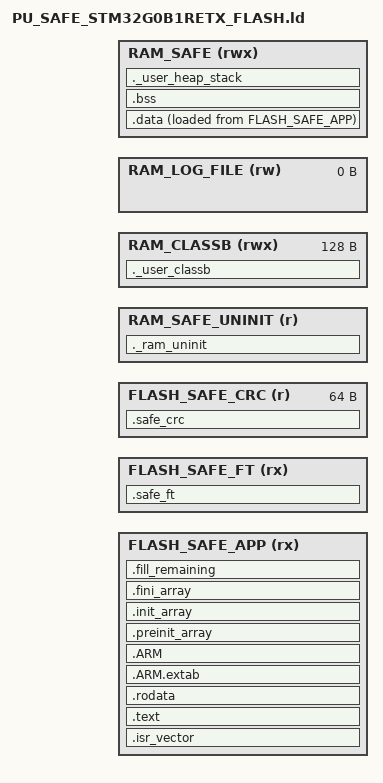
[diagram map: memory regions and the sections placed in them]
/**
 ******************************************************************************
 * @file      LinkerScript.ld
 * @author    Auto-generated by STM32CubeIDE
 * @brief     Linker script for STM32G0B1RETx Device from STM32G0 series
 *                      512Kbytes FLASH
 *                      144Kbytes RAM
 *
 *            Set heap size, stack size and stack location according
 *            to application requirements.
 *
 *            Set memory bank area and size if external memory is used
 ******************************************************************************
 * @attention
 *
 * <h2><center>&copy; Copyright (c) 2020 STMicroelectronics.
 * All rights reserved.</center></h2>
 *
 * This software component is licensed by ST under BSD 3-Clause license,
 * the "License"; You may not use this file except in compliance with the
 * License. You may obtain a copy of the License at:
 *                        opensource.org/licenses/BSD-3-Clause
 *
 ******************************************************************************
 */

/* External linker file common to SAFE and USER project where partitioning 
* of the FLASH and RAM between SAFE and USER project is set.
* All further partitioning of the FLASH and RAM in this file is within boundaries
* set in memory_definition.ld file.*/
INCLUDE ../../submodules/shared/memory_definition.ld


/* Entry Point */
ENTRY(Safe_Reset_Handler)



/*##########################################################################*/
/* Highest address of the user mode stack */
_estack = _MEMPART_RAM_SAFE_ADDR + _MEMPART_RAM_SAFE_SIZE;    /* end of "RAM" Ram type memory */

 

_Min_Heap_Size  = 0x400 ;    /* required amount of heap  */
_Min_Stack_Size = 0x800 ;    /* required amount of stack */

 

/* used at SAFE start to delete whole RAM (SAFE and USER) - NOT USED*/
_ram_start = _RAM_START_ADDR;
_ram_end   = _RAM_START_ADDR + _RAM_SIZE;
 

/* This is related to ClassB Flash CRC runtime check. */
/*Size of the SAFE app + SAFE Function table must be multiple of 64*/
/* CRC of SAFE flash image is located in the last 64 byte block */
/* of the Function table defined in the memory_definition.ld (see INCLUDE above) */
FLASH_SAFE_CRC_SIZE = 64; 

/* Put SAFE FLASH CRC at the end of SAFE_FNC_TABLE */
FLASH_SAFE_CRC_ADDR = _MEMPART_FLASH_SAFE_FNC_TABLE_ADDR + _MEMPART_FLASH_SAFE_FNC_TABLE_SIZE - FLASH_SAFE_CRC_SIZE;


/* Class B variables */
RAM_CLASSB_SIZE = 0x80;
RAM_CLASSB_ADDR = _MEMPART_RAM_SAFE_ADDR;

 /* USED for TEST logging */
RAM_LOG_FILE_SIZE = 0;
RAM_LOG_FILE_ADDR = RAM_CLASSB_ADDR + RAM_CLASSB_SIZE;
_MEMPART_RAM_LOG_FILE_ADDR = RAM_LOG_FILE_ADDR;

/* SAFE RAM minus CLASS B */
RAM_SAFE_MCB_ADDR = RAM_LOG_FILE_ADDR + RAM_LOG_FILE_SIZE; 
RAM_SAFE_MCB_SIZE = _MEMPART_RAM_SAFE_SIZE - RAM_CLASSB_SIZE - RAM_LOG_FILE_SIZE; 


/*##########################################################################*/
/* Memories definition */
MEMORY
{
    FLASH_SAFE_APP  (rx)    : ORIGIN = _MEMPART_FLASH_SAFE_APP_ADDR         ,LENGTH = _MEMPART_FLASH_SAFE_APP_SIZE 
    FLASH_SAFE_FT   (rx)    : ORIGIN = _MEMPART_FLASH_SAFE_FNC_TABLE_ADDR   ,LENGTH = _MEMPART_FLASH_SAFE_FNC_TABLE_SIZE - FLASH_SAFE_CRC_SIZE
    FLASH_SAFE_CRC  (r )    : ORIGIN = FLASH_SAFE_CRC_ADDR                  ,LENGTH = FLASH_SAFE_CRC_SIZE

    RAM_SAFE_UNINIT (r  )   : ORIGIN = _MEMPART_RAM_NMI_TEST_ADDR           ,LENGTH = _MEMPART_RAM_NMI_TEST_SIZE
    RAM_CLASSB      (rwx)   : ORIGIN = RAM_CLASSB_ADDR                      ,LENGTH = RAM_CLASSB_SIZE
    RAM_LOG_FILE    (rw )   : ORIGIN = RAM_LOG_FILE_ADDR                    ,LENGTH = RAM_LOG_FILE_SIZE
    RAM_SAFE        (rwx)   : ORIGIN = RAM_SAFE_MCB_ADDR                    ,LENGTH = RAM_SAFE_MCB_SIZE    
}
 

/*##########################################################################*/
/* Sections */
SECTIONS
{

  /* The startup code into "FLASH_SAFE_APP" Rom type memory */
  .isr_vector :
  {
    . = ALIGN(16);
    _Isr_Vector_Flash = .;
    KEEP(*(.isr_vector)) /* Startup code */
    . = ALIGN(16);
    _isr_section_end = .;
  } >FLASH_SAFE_APP = 0xDEAD

 

  /* The program code and other data into "FLASH_SAFE_APP" Rom type memory
  ** Explicit address because of issues with linker that placed it at 0xC0 
  ** instead of 0xBC and this created 4-byte gap beetween .isr_vector and .text sections. 
  ** This gap causes CRC to fail.  
  */
  .text _isr_section_end : 
  {
    . = ALIGN(16);
     PROVIDE(_stext = .);
    *(.text)           /* .text sections (code) */
    *(.text*)          /* .text* sections (code) */
    *(.glue_7)         /* glue arm to thumb code */
    *(.glue_7t)        /* glue thumb to arm code */
    *(.eh_frame)

    KEEP (*(.init))
    KEEP (*(.fini))

    . = ALIGN(16);
    _etext = .;        /* define a global symbols at end of code */
  } >FLASH_SAFE_APP = 0xDEAD

 

  /* Constant data into "FLASH_SAFE_APP" Rom type memory */
  .rodata :
  {
    . = ALIGN(16);
    *(.rodata)         /* .rodata sections (constants, strings, etc.) */
    *(.rodata*)        /* .rodata* sections (constants, strings, etc.) */
    . = ALIGN(16);
  } >FLASH_SAFE_APP = 0xDEAD

 

  .ARM.extab   : { 
      . = ALIGN(16);
      *(.ARM.extab* .gnu.linkonce.armextab.*)
      . = ALIGN(16);
  } >FLASH_SAFE_APP = 0xDEAD
  
  .ARM : {
    . = ALIGN(16);
    __exidx_start = .;
    *(.ARM.exidx*)
    __exidx_end = .;
    . = ALIGN(8);
  } >FLASH_SAFE_APP = 0xDEAD

  .preinit_array     :
  {
    . = ALIGN(8);
    BYTE(0xBA); /* this byte is to make sure there section isn't empty, so it has an LMA, and doesn't cause a gap */
    PROVIDE_HIDDEN (__preinit_array_start = .);    
    KEEP (*(.preinit_array*))
    PROVIDE_HIDDEN (__preinit_array_end = .);
    . = ALIGN(16);
  } >FLASH_SAFE_APP = 0xDEAD
  
  .init_array :
  {
    . = ALIGN(16);
    PROVIDE_HIDDEN (__init_array_start = .);
    KEEP (*(SORT(.init_array.*)))
    KEEP (*(.init_array*))
    PROVIDE_HIDDEN (__init_array_end = .);
    . = ALIGN(16);
  } >FLASH_SAFE_APP = 0xDEAD
  
  .fini_array :
  {
    . = ALIGN(16);
    PROVIDE_HIDDEN (__fini_array_start = .);
    KEEP (*(SORT(.fini_array.*)))
    KEEP (*(.fini_array*))
    PROVIDE_HIDDEN (__fini_array_end = .);
    . = ALIGN(16);
  } >FLASH_SAFE_APP = 0xDEAD


  /* Used by the startup to initialize data */
  _sidata = LOADADDR(.data);
 

  /* Initialized data sections into "RAM_USER" Ram type memory */
  .data : 
  {
    . = ALIGN(16);
    _sdata = .;        /* create a global symbol at data start */
    *(stm32xx_STLstartup.o)
    *(.data)           /* .data sections */
    *(.data*)          /* .data* sections */

 

    . = ALIGN(16);
    PROVIDE_HIDDEN (_edata = .);        /* define a global symbol at data end */
    
  } >RAM_SAFE AT> FLASH_SAFE_APP = 0xDEAD


  /* Fill the remaining FLASH_SAFE_APP to have correct CRC calculated for ELF file*/
  .fill_remaining :
  {
    FILL(0xBABE);
    . = ORIGIN(FLASH_SAFE_APP) + LENGTH(FLASH_SAFE_APP) - 1;
    BYTE(0xAA)
  } > FLASH_SAFE_APP

  
  /* Struct with pointers to safe functions into "FLASH_SAFE_FT" Rom type memory */
  .safe_ft :
  {
    . = ALIGN(16);
    _safe_ft_start = .;
    *(.safe_ft)         /* .safe_ft  safe functions pointer table */
    *(.safe_ft*)        /* .safe_ft* safe functions pointer table */
    KEEP (*(.safe_ft*))
    /* Fill up the rest of the table */
    FILL(0xBEEF);    
    . = _safe_ft_start + (_MEMPART_FLASH_SAFE_FNC_TABLE_SIZE - FLASH_SAFE_CRC_SIZE);
  } >FLASH_SAFE_FT


  /* Location for CRC of FLASH_SAFE_APP + FLASH_SAFE_FT  */
  .safe_crc :
  {
    . = ALIGN(FLASH_SAFE_CRC_SIZE);
    PROVIDE(_Safe_Crc = .);
    LONG(0x58585858); /* XXXX - dummy value, overwritten by CRC calculation script*/
    
  } >FLASH_SAFE_CRC
  
  
  
/*###########################################################################*/
/*###################### CLASS B ############################################*/
/*###########################################################################*/

  /* User class B RAM region */
  ._user_classb(NOLOAD) :
  {
    . = ALIGN(4);
    *(.run_time_ram_buf)
    *(.run_time_ram_buf*)
    *(.run_time_ram_pnt)
    *(.run_time_ram_pnt*)
    
    . = ALIGN(4);
    PROVIDE(_classb_start = . );
    
    *(.class_b_ram)
    *(.class_b_ram*)
    . = ALIGN(4);
    *(.class_b_ram_rev)
    *(.class_b_ram_rev*)
    
    . = ALIGN(4);
    PROVIDE(_classb_end = . );
  } >RAM_CLASSB


  /*##########################################################################*/
  /* Uninitialized data section into "RAM_USER" RAM type memory */

  . = ALIGN(4);
  .bss(NOLOAD) :
  {
    /* This is used by the startup in order to initialize the .bss secion */
    _sbss = .;         /* define a global symbol at bss start */
    __bss_start__ = _sbss;
    *(.bss)
    *(.bss*)
    *(COMMON)

    . = ALIGN(4);
    _ebss = .;         /* define a global symbol at bss end */
    __bss_end__ = _ebss;
  } >RAM_SAFE


  /* User_heap_stack section, used to check that there is enough "RAM_USER" Ram  type memory left */
  ._user_heap_stack(NOLOAD) :
  {
    . = ALIGN(8);
    PROVIDE ( end = . );
    PROVIDE ( _end = . );
    . = . + _Min_Heap_Size;
    *(.stack_bottom)
    *(.stack_bottom*)    
    . = . + _Min_Stack_Size;
    . = ALIGN(8);
  } >RAM_SAFE

  /* Uninitialized section of RAM used to generate NMI SRAM partiy exception */ 
  ._ram_uninit(NOLOAD):
  {
    KEEP (*(._ram_uninit ));
    KEEP (*(._ram_uninit*));
  } > RAM_SAFE_UNINIT

  /* Remove information from the compiler libraries */
  /DISCARD/ :
  {
    libc.a ( * )
    libm.a ( * )
    libgcc.a ( * )
  }

  .ARM.attributes 0 : { *(.ARM.attributes) }
}

